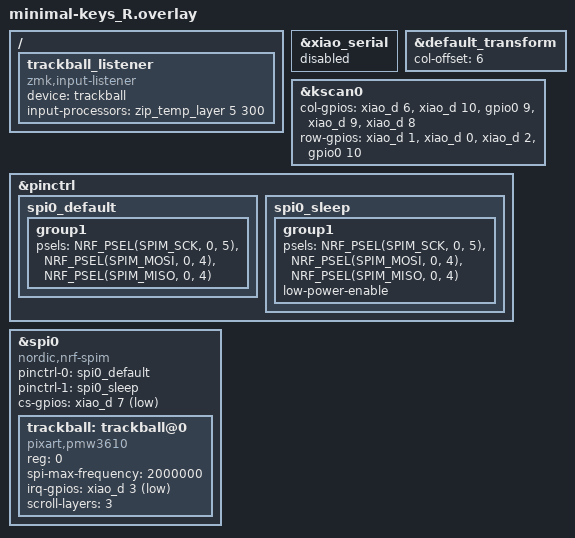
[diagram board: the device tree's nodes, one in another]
#include "minimal-keys.dtsi"
#include <dt-bindings/input/input-event-codes.h>
#include <input/processors/runtime-input-processor.dtsi>
#include <input/processors.dtsi>
&xiao_serial { status = "disabled"; };
&default_transform {
    col-offset = <6>;
};

&kscan0 {
    col-gpios
        = <&xiao_d 6 GPIO_ACTIVE_HIGH>   // Col0: P1.11_D6_TX
        , <&xiao_d 10 GPIO_ACTIVE_HIGH>  // Col1: P1.15_D10_MOSI
        , <&gpio0 9 GPIO_ACTIVE_HIGH>    // Col2: P0.09 (NFC1)
        , <&xiao_d 9 GPIO_ACTIVE_HIGH>   // Col3: P1.14_D9_MISO
        , <&xiao_d 8 GPIO_ACTIVE_HIGH>   // Col4: P1.13_D8_SCK
        ;
    row-gpios 
        = <&xiao_d 1 (GPIO_ACTIVE_HIGH | GPIO_PULL_DOWN)>  // Row0 (P0.03)
        , <&xiao_d 0 (GPIO_ACTIVE_HIGH | GPIO_PULL_DOWN)>  // Row1 (P0.02)
        , <&xiao_d 2 (GPIO_ACTIVE_HIGH | GPIO_PULL_DOWN)> // Row2 (P0.28)
        , <&gpio0 10 (GPIO_ACTIVE_HIGH | GPIO_PULL_DOWN)> // Row3 (動作確認済み)
        ;
};

&pinctrl {
    spi0_default: spi0_default {
        group1 {
            psels = <NRF_PSEL(SPIM_SCK, 0, 5)>,
                <NRF_PSEL(SPIM_MOSI, 0, 4)>,
                <NRF_PSEL(SPIM_MISO, 0, 4)>;
        };
    };

    spi0_sleep: spi0_sleep {
        group1 {
            psels = <NRF_PSEL(SPIM_SCK, 0, 5)>,
                <NRF_PSEL(SPIM_MOSI, 0, 4)>,
                <NRF_PSEL(SPIM_MISO, 0, 4)>;
            low-power-enable;
        };
    };
};

/ {
    trackball_listener {
        compatible = "zmk,input-listener";
        device = <&trackball>;
        input-processors = <&mouse_runtime_input_processor>;
    };

    trackball_listener :trackball_listener {
        compatible = "zmk,input-listener";
        device = <&trackball>;
        input-processors = <&zip_temp_layer 5 300>;
    };

};

&spi0 {
    status = "okay";
    compatible = "nordic,nrf-spim";
    pinctrl-0 = <&spi0_default>;
    pinctrl-1 = <&spi0_sleep>;
    pinctrl-names = "default", "sleep";
    cs-gpios = <&xiao_d 7 GPIO_ACTIVE_LOW>;

    trackball: trackball@0 {
        status = "okay";
        compatible = "pixart,pmw3610";
        reg = <0>;
        spi-max-frequency = <2000000>;
        irq-gpios = <&xiao_d 3 (GPIO_ACTIVE_LOW | GPIO_PULL_UP)>;
        scroll-layers = <3>;
    };
};
